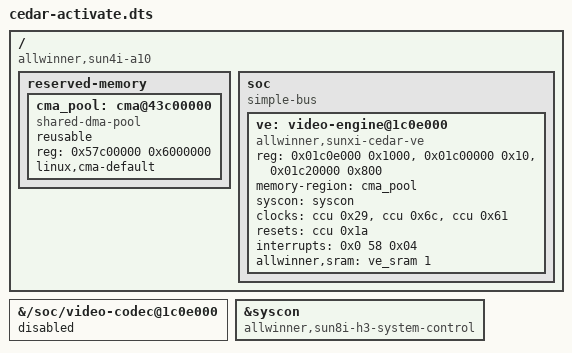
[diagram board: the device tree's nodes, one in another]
/dts-v1/;
/plugin/;

/ {
	compatible = "allwinner,sun4i-a10", "allwinner,sun7i-a20", "allwinner,sun8i-h3", "allwinner,sun50i-a64", "allwinner,sun50i-h5";

	fragment@0 {
		target-path = "/";
		__overlay__ {
			reserved-memory {
                		#address-cells = <0x01>;
                		#size-cells = <0x01>;
                		ranges;

                		cma_pool: cma@43c00000 {
                        		compatible = "shared-dma-pool";
                        		reusable;
                        		reg = <0x57c00000 0x6000000>;
                        		linux,cma-default;
                        		status = "okay";
               			};
			};

			soc {
				compatible = "simple-bus";
				#address-cells = <0x01>;
				#size-cells = <0x01>;
				
				ve: video-engine@1c0e000 {
					compatible = "allwinner,sunxi-cedar-ve";
					reg = <0x01c0e000 0x1000>,
					          <0x01c00000 0x10>,
					          <0x01c20000 0x800>;
					memory-region = <&cma_pool>;
					syscon = <&syscon>;
					clocks = <&ccu 0x29>, <&ccu 0x6c>, //CLK_BUS_VE, CLK_VE
					         <&ccu 0x61>; //CLK_DRAM_VE
					clock-names = "ahb", "mod", "ram";
					resets = <&ccu 0x1a>; //RST_BUS_VE
					interrupts = <0x0 58 0x04>; //GIC_SPI, 58, IRQ_TYPE_LEVEL_HIGH
					allwinner,sram = <&ve_sram 1>;
					status = "okay";
				};
			};
		};
	};

	fragment@1 {
		target-path = "/soc/video-codec@1c0e000";
		__overlay__ {
			status = "disabled";
		};
	};

	fragment@2 {
		target = <&syscon>;
		__overlay__ {
			compatible = "allwinner,sun8i-h3-system-control","syscon"; //add syscon module load
		};
	};
};
